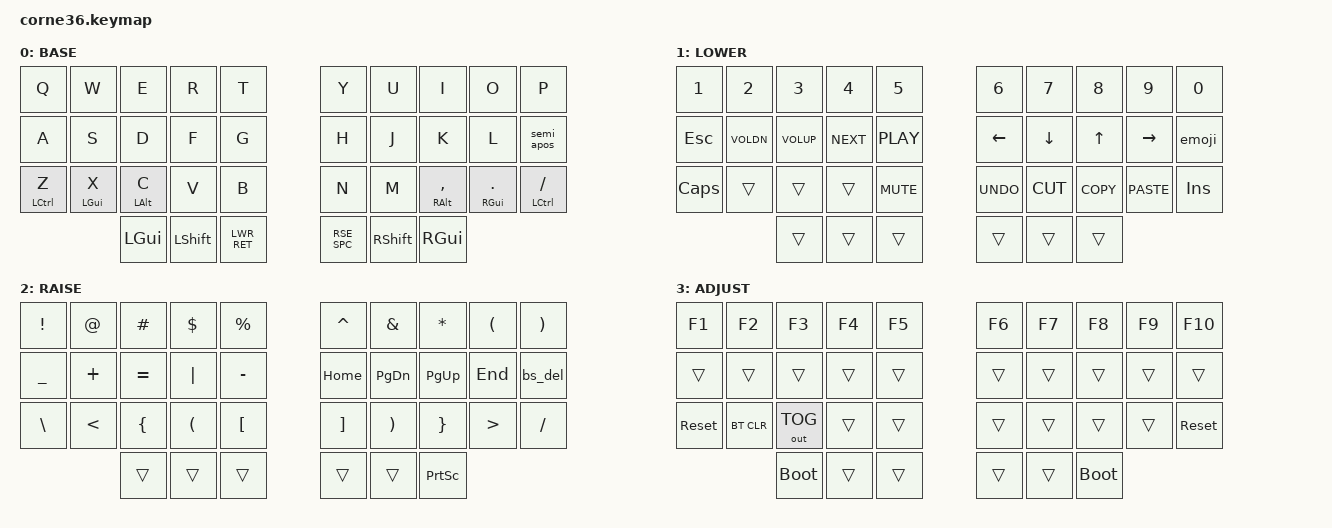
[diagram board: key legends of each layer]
// Layer Definitions
#define DEFAULT 0
#define LOWER 1
#define RAISE 2
#define ADJUST 3


#include <behaviors.dtsi>
#include <dt-bindings/zmk/keys.h>
#include <dt-bindings/zmk/bt.h>
#include <dt-bindings/zmk/outputs.h>
#include <dt-bindings/zmk/ext_power.h>

#include "includes/settings.dtsi"
#include "includes/combos.dtsi"
#include "includes/behaviors_extra.dtsi"
#include "includes/conditional_layers.dtsi"
#include "includes/custom_keycodes.dtsi"
#include "includes/macros.dtsi"
#include "includes/settings_pd.dtsi"

/ {
    chosen {
        zmk,matrix_transform = &five_column_transform;
    };

    keymap {
        compatible = "zmk,keymap";
        default_layer {
            label = "BASE";
            bindings = <
        //╭──────────┬──────────┬──────────┬──────────┬──────────╮   ╭──────────┬──────────┬──────────┬──────────┬──────────╮
        //|    Q     |    W     |    E     |    R     |    T     |   |    Y     |    U     |    I     |    O     |    P     |
            &kp Q      &kp W      &kp E      &kp R      &kp T          &kp Y      &kp U      &kp I      &kp O      &kp P
        //├──────────┼──────────┼──────────┼──────────┼──────────┤   ├──────────┼──────────┼──────────┼──────────┼──────────┤
        //|    A     |    S     |    D     |    F     |    G     |   |    H     |    J     |    K     |    L     |    ;/'   |
            &kp A      &kp S      &kp D      &kp F      &kp G          &kp H      &kp J      &kp K      &kp L      &semi_apos
        //├──────────┼──────────┼──────────┼──────────┼──────────┤   ├──────────┼──────────┼──────────┼──────────┼──────────┤
        //|    Z     |    X     |    C     |    V     |    B     |   |    N     |    M     |    ,     |    .     |    /     |
           &hml LCTRL Z &hml LGUI X &hml LALT C  &kp V  &kp B          &kp N      &kp M   &hmr RALT COMMA &hmr RGUI DOT &hmr LCTRL FSLH
        //╰──────────┴──────────┼──────────┼──────────┼──────────┤   ├──────────┼──────────┼──────────┼──────────┴──────────╯
        //                      |   GUI    |   LSFT   |   ENT    |   |  SPACE   |  RSHFT   |   GUI    |
                                  &kp LGUI  &kp LSHFT   LWR_RET        RSE_SPC   &kp RSHFT &kp RGUI
        //                      ╰──────────┴──────────┴──────────╯   ╰──────────┴──────────┴──────────╯
            >;
        };

        lower_layer {
            label = "LOWER";
            bindings = <
        //╭──────────┬──────────┬──────────┬──────────┬──────────╮   ╭──────────┬──────────┬──────────┬──────────┬──────────╮
        //|    1     |    2     |    3     |    4     |    5     |   |    6     |    7     |    8     |    9     |    0     |
            &kp N1     &kp N2     &kp N3     &kp N4     &kp N5         &kp N6     &kp N7     &kp N8     &kp N9     &kp N0
        //├──────────┼──────────┼──────────┼──────────┼──────────┤   ├──────────┼──────────┼──────────┼──────────┼──────────┤
        //|   ESC    | VOL DWN  |  VOL UP  |   NEXT   |   PLAY   |   |    UP    |   DOWN   |   LEFT   |  RIGHT   |  EMOJI   |
            &kp ESC   &kp VOLDN   &kp VOLUP &kp K_NEXT &kp C_PLAY      &kp LEFT   &kp DOWN   &kp UP     &kp RIGHT &emoji
        //├──────────┼──────────┼──────────┼──────────┼──────────┤   ├──────────┼──────────┼──────────┼──────────┼──────────┤
        //|          |          |          |          |   MUTE   |   |   UNDO   |   CUT    |   COPY   |   PASTE  |  INSERT  |
            &kp CAPS    &trans     &trans     &trans   &kp C_MUTE     &kp K_UNDO &kp K_CUT  &kp K_COPY &kp K_PASTE &kp INS
        //╰──────────┴──────────┼──────────┼──────────┼──────────┤   ├──────────┼──────────┼──────────┼──────────┴──────────╯
        //                      |          |          |          |   |          |          |          |
                                  &trans     &trans     &trans         &trans     &trans     &trans
        //                      ╰──────────┴──────────┴──────────╯   ╰──────────┴──────────┴──────────╯
            >;
        };

        raise_layer {
            label = "RAISE";
            bindings = <
        //╭──────────┬──────────┬──────────┬──────────┬──────────╮   ╭──────────┬──────────┬──────────┬──────────┬──────────╮
        //|    !     |    @     |    #     |    $     |    %     |   |    ^     |    &     |    *     |    (     |     )    |
            &kp EXCL   &kp AT     &kp HASH   &kp DLLR  &kp PRCNT      &kp CARET   &kp AMPS  &kp ASTRK   &kp LPAR   &kp RPAR
        //├──────────┼──────────┼──────────┼──────────┼──────────┤   ├──────────┼──────────┼──────────┼──────────┼──────────┤
        //|    _     |    +     |    =     |    |     |    -     |   |   HOME   |   PGDN   |   PGUP   |   END    |   BSPC   |
            &kp UNDER  &kp PLUS   &kp EQUAL  &kp PIPE   &kp MINUS      &kp HOME   &kp PG_DN  &kp PG_UP  &kp END    &bs_del
        //├──────────┼──────────┼──────────┼──────────┼──────────┤   ├──────────┼──────────┼──────────┼──────────┼──────────┤
        //|    \     |    <     |    {     |    (     |    [     |   |    ]     |    )     |    }     |    >     |    /     |
            &kp BSLH    &kp LT    &kp LBRC   &kp LPAR   &kp LBKT       &kp RBKT   &kp RPAR   &kp RBRC    &kp GT    &kp FSLH
        //╰──────────┴──────────┼──────────┼──────────┼──────────┤   ├──────────┼──────────┼──────────┼──────────┴──────────╯
        //                      |          |          |          |   |          |          |  PSCRN   |
                                    &trans     &trans     &trans         &trans     &trans  &kp PSCRN
        //                      ╰──────────┴──────────┴──────────╯   ╰──────────┴──────────┴──────────╯
            >;
        };

        adjust_layer {
            label = "ADJUST";
            bindings = <
        //╭──────────┬──────────┬──────────┬──────────┬──────────╮   ╭──────────┬──────────┬──────────┬──────────┬──────────╮
        //|    F1    |    F2    |    F3    |    F4    |    F5    |   |    F6    |    F7    |    F8    |    F9    |   F10    |
            &kp F1     &kp F2     &kp F3     &kp F4     &kp F5         &kp F6     &kp F7     &kp F8     &kp F9     &kp F10
        //├──────────┼──────────┼──────────┼──────────┼──────────┤   ├──────────┼──────────┼──────────┼──────────┼──────────┤
        //|          |          |          |          |          |   |          |          |          |          |          |
            &trans     &trans     &trans     &trans     &trans         &trans     &trans     &trans     &trans     &trans
        //├──────────┼──────────┼──────────┼──────────┼──────────┤   ├──────────┼──────────┼──────────┼──────────┼──────────┤
        //|  RESET   |  BTCLR   | USB/BT   |          |          |   |          |          |          |          | RESET    |
            &sys_reset &bt BT_CLR &out OUT_TOG &trans   &trans         &trans     &trans     &trans     &trans     &sys_reset
        //╰──────────┴──────────┼──────────┼──────────┼──────────┤   ├──────────┼──────────┼──────────┼──────────┴──────────╯
        //                      |          |          |          |   |          |          |          |
                                 &bootloader  &trans     &trans        &trans     &trans    &bootloader
        //                      ╰──────────┴──────────┴──────────╯   ╰──────────┴──────────┴──────────╯
            >;

        };
    };
};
